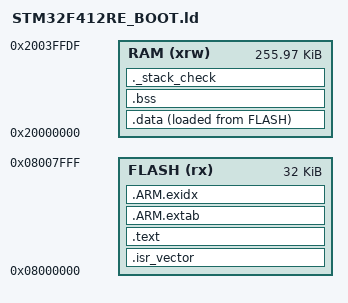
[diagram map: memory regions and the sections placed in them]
/*
 * Bootloader do BMS: S0+S1 (32 KB) da flash. A RAM acaba 32 B antes do fim:
 * 0x2003FFE0..0x2003FFFF e a area partilhada com a aplicacao (boot_shared.h).
 */

ENTRY(Reset_Handler)

MEMORY
{
  FLASH (rx)  : ORIGIN = 0x08000000, LENGTH = 32K
  RAM   (xrw) : ORIGIN = 0x20000000, LENGTH = 256K - 32
}

_estack = ORIGIN(RAM) + LENGTH(RAM);
_Min_Stack_Size = 0x1000;

SECTIONS
{
  .isr_vector :
  {
    . = ALIGN(4);
    KEEP(*(.isr_vector))
    . = ALIGN(4);
  } >FLASH

  .text :
  {
    . = ALIGN(4);
    *(.text)
    *(.text*)
    *(.rodata)
    *(.rodata*)
    *(.glue_7)
    *(.glue_7t)
    . = ALIGN(4);
    _etext = .;
  } >FLASH

  .ARM.extab : { *(.ARM.extab* .gnu.linkonce.armextab.*) } >FLASH
  .ARM.exidx : { *(.ARM.exidx* .gnu.linkonce.armexidx.*) } >FLASH

  _sidata = LOADADDR(.data);

  .data :
  {
    . = ALIGN(4);
    _sdata = .;
    *(.data)
    *(.data*)
    . = ALIGN(4);
    _edata = .;
  } >RAM AT> FLASH

  .bss (NOLOAD) :
  {
    . = ALIGN(4);
    _sbss = .;
    *(.bss)
    *(.bss*)
    *(COMMON)
    . = ALIGN(4);
    _ebss = .;
  } >RAM

  end = _ebss;
  _end = _ebss;

  /* a pilha cabe na RAM que sobra */
  ._stack_check (NOLOAD) :
  {
    . = ALIGN(8);
    . = . + _Min_Stack_Size;
  } >RAM
}
